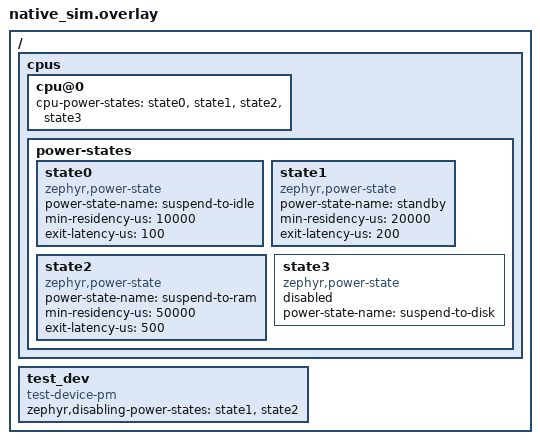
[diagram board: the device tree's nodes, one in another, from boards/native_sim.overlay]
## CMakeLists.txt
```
# Copyright (c) 2020 Intel Corporation.
# SPDX-License-Identifier: Apache-2.0

cmake_minimum_required(VERSION 3.20.0)

find_package(Zephyr REQUIRED HINTS $ENV{ZEPHYR_BASE})
project(pm-states-test)

target_sources(app PRIVATE src/main.c src/test_driver.c)
```

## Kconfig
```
# Copyright (c) 2023 Intel Corporation
# SPDX-License-Identifier: Apache-2.0

menu "Zephyr"
source "Kconfig.zephyr"
endmenu

config TEST_PROVIDE_PM_HOOKS
	bool "Provide PM hooks for test purposes"
	default y
	select HAS_PM
```

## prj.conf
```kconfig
CONFIG_PM=y
CONFIG_PM_DEVICE=y
CONFIG_PM_POLICY_DEVICE_CONSTRAINTS=y
CONFIG_ZTEST=y
```

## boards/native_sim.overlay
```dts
/*
 * Copyright (c) 2020, Intel Corporation
 *
 * SPDX-License-Identifier: Apache-2.0
 */

/ {
	cpus {
		cpu@0 {
			cpu-power-states = <&state0 &state1 &state2 &state3>;
		};

		power-states {
			state0: state0 {
				compatible = "zephyr,power-state";
				power-state-name = "suspend-to-idle";
				min-residency-us = <10000>;
				exit-latency-us = <100>;
			};

			state1: state1 {
				compatible = "zephyr,power-state";
				power-state-name = "standby";
				min-residency-us = <20000>;
				exit-latency-us = <200>;
			};

			state2: state2 {
				compatible = "zephyr,power-state";
				power-state-name = "suspend-to-ram";
				min-residency-us = <50000>;
				exit-latency-us = <500>;
			};

			state3: state3 {
				compatible = "zephyr,power-state";
				power-state-name = "suspend-to-disk";
				status = "disabled";
			};
		};
	};

	test_dev: test_dev {
		compatible = "test-device-pm";
		status = "okay";
		zephyr,disabling-power-states = <&state1 &state2>;
	};
};
```

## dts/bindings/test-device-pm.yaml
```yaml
# Copyright (c) 2024 Intel Corporation.
# SPDX-License-Identifier: Apache-2.0

include: [base.yaml, pm.yaml]

description: |
  This binding provides resources required to build and run the
  tests/subsys/pm/power_states_api test in Zephyr.

compatible: "test-device-pm"
```

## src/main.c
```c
/*
 * Copyright (c) 2020 Intel Corporation.
 *
 * SPDX-License-Identifier: Apache-2.0
 */

#include "test_driver.h"

#include <zephyr/device.h>
#include <zephyr/kernel.h>
#include <zephyr/ztest.h>
#include <zephyr/pm/pm.h>

/* Last state has not declared a minimum residency, so it should be
 * set the default 0 value
 */
static struct pm_state_info infos[] = {{PM_STATE_SUSPEND_TO_IDLE, 0, 10000, 100},
	       {PM_STATE_STANDBY, 0, 20000, 200}, {PM_STATE_SUSPEND_TO_RAM, 0, 50000, 500}};
static enum pm_state states[] = {PM_STATE_SUSPEND_TO_IDLE,
			PM_STATE_STANDBY, PM_STATE_SUSPEND_TO_RAM};
static enum pm_state wrong_states[] = {PM_STATE_SUSPEND_TO_DISK,
		PM_STATE_SUSPEND_TO_RAM, PM_STATE_SUSPEND_TO_RAM};

static uint8_t suspend_to_ram_count;

void pm_state_set(enum pm_state state, uint8_t substate_id)
{
	ARG_UNUSED(substate_id);

	if (state == PM_STATE_SUSPEND_TO_RAM) {
		suspend_to_ram_count++;
	}

	k_cpu_idle();
}

void pm_state_exit_post_ops(enum pm_state state, uint8_t substate_id)
{
	ARG_UNUSED(state);
	ARG_UNUSED(substate_id);

	irq_unlock(0);
}

ZTEST(power_states_1cpu, test_power_states)
{
	uint8_t ret;
	const struct pm_state_info *cpu_states;
	enum pm_state dts_states[] =
		PM_STATE_LIST_FROM_DT_CPU(DT_NODELABEL(cpu0));
	struct pm_state_info dts_infos[] =
		PM_STATE_INFO_LIST_FROM_DT_CPU(DT_NODELABEL(cpu0));
	uint32_t dts_states_len =
		DT_NUM_CPU_POWER_STATES(DT_NODELABEL(cpu0));

	zassert_true(ARRAY_SIZE(states) == dts_states_len,
		     "Invalid number of pm states");
	zassert_true(memcmp(infos, dts_infos, ARRAY_SIZE(dts_infos)) == 0,
		     "Invalid pm_state_info array");
	zassert_true(memcmp(states, dts_states, ARRAY_SIZE(dts_states)) == 0,
		     "Invalid pm-states array");

	zassert_false(memcmp(wrong_states, dts_states, ARRAY_SIZE(dts_states)) == 0,
		     "Invalid pm-states array");

	ret = pm_state_cpu_get_all(CONFIG_MP_MAX_NUM_CPUS + 1, &cpu_states);
	zassert_true(ret == 0, "Invalid pm_state_cpu_get_all return");

	ret = pm_state_cpu_get_all(0U, &cpu_states);
	zassert_true(ret == dts_states_len,
		     "Invalid number of pm states");
	zassert_true(memcmp(cpu_states, dts_infos, ARRAY_SIZE(dts_infos)) == 0,
		     "Invalid pm_state_info array");
}

ZTEST(power_states_1cpu, test_device_power_state_constraints)
{
	static const struct device *const dev =
		DEVICE_DT_GET(DT_NODELABEL(test_dev));
	suspend_to_ram_count = 0;

	test_driver_async_operation(dev);

	/** Lets sleep long enough to suspend the CPU with `suspend to ram`
	 *  power state. If everything works well the cpu should not use this
	 *  state due the constraint set by `test_dev`.
	 */
	k_sleep(K_USEC(60000));

	zassert_true(suspend_to_ram_count == 0, "Invalid suspend to ram count");

	/** Now lets check ensure that if there is no ongoing work
	 *  the cpu will suspend to ram.
	 */
	k_sleep(K_MSEC(600));

	zassert(suspend_to_ram_count != 0, "Not suspended to ram");
}

ZTEST_SUITE(power_states_1cpu, NULL, NULL, ztest_simple_1cpu_before,
			ztest_simple_1cpu_after, NULL);
```

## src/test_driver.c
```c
/*
 * Copyright (c) 2024 Intel Corporation
 *
 * SPDX-License-Identifier: Apache-2.0
 */

#include "test_driver.h"

#include <zephyr/kernel.h>
#include <zephyr/pm/policy.h>
#include <zephyr/pm/device.h>
#include <zephyr/ztest.h>

struct test_driver_data {
	const struct device *self;
	struct k_timer timer;
	bool ongoing;
};

static int test_driver_action(const struct device *dev,
			      enum pm_device_action action)
{
	ARG_UNUSED(dev);
	ARG_UNUSED(action);

	return 0;
}

static void timer_expire_cb(struct k_timer *timer)
{
	struct test_driver_data *data = k_timer_user_data_get(timer);

	data->ongoing = false;
	k_timer_stop(timer);
	pm_policy_device_power_lock_put(data->self);
}

void test_driver_async_operation(const struct device *dev)
{
	struct test_driver_data *data = dev->data;

	data->ongoing = true;
	pm_policy_device_power_lock_get(dev);

	/** Lets set a timer big enough to ensure that any deep
	 *  sleep state would be suitable but constraints will
	 *  make only state0 (suspend-to-idle) will be used.
	 */
	k_timer_start(&data->timer, K_MSEC(500), K_NO_WAIT);
}

int test_driver_init(const struct device *dev)
{
	struct test_driver_data *data = dev->data;

	data->self = dev;

	k_timer_init(&data->timer, timer_expire_cb, NULL);
	k_timer_user_data_set(&data->timer, data);

	return 0;
}

PM_DEVICE_DT_DEFINE(DT_NODELABEL(test_dev), test_driver_action);

static struct test_driver_data data;

DEVICE_DT_DEFINE(DT_NODELABEL(test_dev), test_driver_init,
	      PM_DEVICE_DT_GET(DT_NODELABEL(test_dev)), &data, NULL, POST_KERNEL,
	      CONFIG_KERNEL_INIT_PRIORITY_DEVICE, NULL);
```

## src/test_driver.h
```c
/*
 * Copyright (c) 2024 Intel Corporation.
 *
 * SPDX-License-Identifier: Apache-2.0
 */

#ifndef TESTS_SUBSYS_PM_POWER_STATES_API_TEST_DRIVER_H_
#define TESTS_SUBSYS_PM_POWER_STATES_API_TEST_DRIVER_H_

#include <zephyr/device.h>

/**
 * @brief Async operation.
 *
 * The device simulates an async operation and shall
 * not be suspended while is in progress. This included
 * the SoC not transition to certain power states.
 *
 * @param dev Device instance.
 */
void test_driver_async_operation(const struct device *dev);


#endif /* TESTS_SUBSYS_PM_POWER_STATES_API_TEST_DRIVER_H_ */
```
